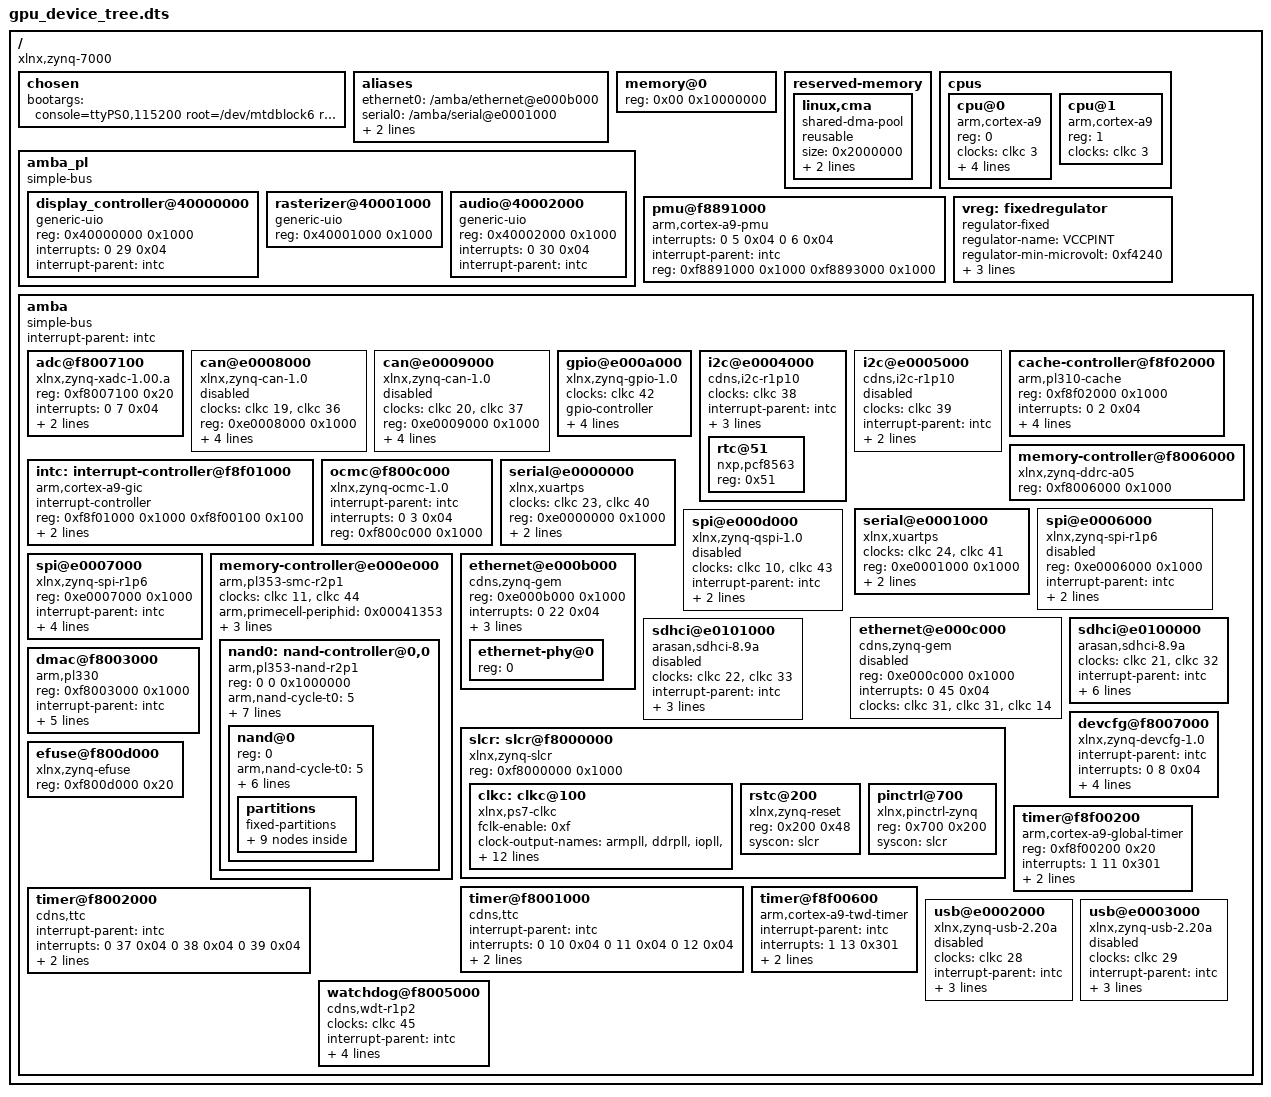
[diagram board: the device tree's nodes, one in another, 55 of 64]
/dts-v1/;

/* IRQ reference */
/* https://www.kernel.org/doc/Documentation/devicetree/bindings/interrupt-controller/arm%2Cgic.txt */
/* https://docs.xilinx.com/r/en-US/ug585-zynq-7000-SoC-TRM/Shared-Peripheral-Interrupts-SPI?tocId=LGXkQnG10uJNPCT_l2ZhDQ */
/* Subtract 32 from IRQ ID# in UG585 */

/ {
    #address-cells = <1>;
    #size-cells = <1>;
    compatible = "xlnx,zynq-7000";

    chosen {
        bootargs = "console=ttyPS0,115200 root=/dev/mtdblock6 rootfstype=jffs2 noinitrd rw rootwait uio_pdrv_genirq.of_id=generic-uio";
    };

    aliases {
        ethernet0 = "/amba/ethernet@e000b000";
        serial0 = "/amba/serial@e0001000";
        serial1 = "/amba/serial@e0000000";
        spi0 = "/amba/spi@e0007000";
    };

    memory@0 {
        device_type = "memory";
        reg = <0x00 0x10000000>;
    };

    reserved-memory {
        #address-cells = <1>;
        #size-cells = <1>;
        ranges;

        linux,cma {
            compatible = "shared-dma-pool";
            reusable;
            size = <0x2000000>;
            alignment = <0x1000>;
            linux,cma-default;
        };
    };

    amba_pl {
        #address-cells = <1>;
        #size-cells = <1>;
        compatible = "simple-bus";
        ranges;

        display_controller@40000000 {
            compatible = "generic-uio";
            reg = <0x40000000 0x1000>;
            interrupts = <0 29 0x04>;
            interrupt-parent = <&intc>;
        };

        rasterizer@40001000 {
            compatible = "generic-uio";
            reg = <0x40001000 0x1000>;
        };

        audio@40002000 {
            compatible = "generic-uio";
            reg = <0x40002000 0x1000>;
            interrupts = <0 30 0x04>;
            interrupt-parent = <&intc>;
        };
    };

    cpus {
        #address-cells = <1>;
        #size-cells = <0>;

        cpu@0 {
            compatible = "arm,cortex-a9";
            device_type = "cpu";
            reg = <0>;
            clocks = <&clkc 3>; /* cpu_6or4x */
            clock-latency = <0x3e8>;
            cpu0-supply = <&vreg>;
            operating-points = <0xa2c29 0xf4240 0x51614 0xf4240>;
        };

        cpu@1 {
            compatible = "arm,cortex-a9";
            device_type = "cpu";
            reg = <1>;
            clocks = <&clkc 3>; /* cpu_6or4x */
        };
    };

    pmu@f8891000 {
        compatible = "arm,cortex-a9-pmu";
        interrupts = <
            0 5 0x04
            0 6 0x04
        >;
        interrupt-parent = <&intc>;
        reg = <0xf8891000 0x1000 0xf8893000 0x1000>;
    };

    vreg: fixedregulator {
        compatible = "regulator-fixed";
        regulator-name = "VCCPINT";
        regulator-min-microvolt = <0xf4240>;
        regulator-max-microvolt = <0xf4240>;
        regulator-boot-on;
        regulator-always-on;
    };

    amba {
        compatible = "simple-bus";
        #address-cells = <1>;
        #size-cells = <1>;
        interrupt-parent = <&intc>;
        ranges;

        adc@f8007100 {
            compatible = "xlnx,zynq-xadc-1.00.a";
            reg = <0xf8007100 0x20>;
            interrupts = <0 7 0x04>;
            interrupt-parent = <&intc>;
            clocks = <&clkc 12>; /* pcap */
        };

        can@e0008000 {
            compatible = "xlnx,zynq-can-1.0";
            status = "disabled";
            clocks = <&clkc 19 &clkc 36>; /* can0, can0_aper */
            clock-names = "can_clk", "pclk";
            reg = <0xe0008000 0x1000>;
            interrupts = <0 28 0x04>;
            interrupt-parent = <&intc>;
            tx-fifo-depth = <0x40>;
            rx-fifo-depth = <0x40>;
        };

        can@e0009000 {
            compatible = "xlnx,zynq-can-1.0";
            status = "disabled";
            clocks = <&clkc 20 &clkc 37>; /* can1, can1_aper */
            clock-names = "can_clk", "pclk";
            reg = <0xe0009000 0x1000>;
            interrupts = <0 51 0x04>;
            interrupt-parent = <&intc>;
            tx-fifo-depth = <0x40>;
            rx-fifo-depth = <0x40>;
        };

        gpio@e000a000 {
            compatible = "xlnx,zynq-gpio-1.0";
            #gpio-cells = <2>;
            clocks = <&clkc 42>; /* gpio_aper */
            gpio-controller;
            interrupt-controller;
            #interrupt-cells = <2>;
            interrupt-parent = <&intc>;
            interrupts = <0 20 0x04>;
            reg = <0xe000a000 0x1000>;
        };

        i2c@e0004000 {
            compatible = "cdns,i2c-r1p10";
            status = "okay";
            clocks = <&clkc 38>; /* i2c0_aper */
            interrupt-parent = <&intc>;
            interrupts = <0 25 0x04>;
            reg = <0xe0004000 0x1000>;
            #address-cells = <1>;
            #size-cells = <0>;
            clock-frequency = <0x61a80>;

            rtc@51 {
                compatible = "nxp,pcf8563";
                reg = <0x51>;
            };
        };

        i2c@e0005000 {
            compatible = "cdns,i2c-r1p10";
            status = "disabled";
            clocks = <&clkc 39>; /* i2c1_aper */
            interrupt-parent = <&intc>;
            interrupts = <0 48 0x04>;
            reg = <0xe0005000 0x1000>;
            #address-cells = <1>;
            #size-cells = <0>;
        };

        intc: interrupt-controller@f8f01000 {
            compatible = "arm,cortex-a9-gic";
            #interrupt-cells = <3>;
            interrupt-controller;
            reg = <0xf8f01000 0x1000 0xf8f00100 0x100>;
            num_cpus = <0x02>;
            num_interrupts = <0x60>;
        };

        cache-controller@f8f02000 {
            compatible = "arm,pl310-cache";
            reg = <0xf8f02000 0x1000>;
            interrupts = <0 2 0x04>;
            arm,data-latency = <0x03 0x02 0x02>;
            arm,tag-latency = <0x02 0x02 0x02>;
            cache-unified;
            cache-level = <2>;
        };

        memory-controller@f8006000 {
            compatible = "xlnx,zynq-ddrc-a05";
            reg = <0xf8006000 0x1000>;
        };

        ocmc@f800c000 {
            compatible = "xlnx,zynq-ocmc-1.0";
            interrupt-parent = <&intc>;
            interrupts = <0 3 0x04>;
            reg = <0xf800c000 0x1000>;
        };

        serial@e0000000 {
            compatible = "xlnx,xuartps", "cdns,uart-r1p8";
            status = "okay";
            clocks = <&clkc 23 &clkc 40>; /* uart0, uart0_aper */
            clock-names = "uart_clk", "pclk";
            reg = <0xe0000000 0x1000>;
            interrupts = <0 27 0x04>;
            device_type = "serial";
            port-number = <1>;
        };

        serial@e0001000 {
            compatible = "xlnx,xuartps", "cdns,uart-r1p8";
            status = "okay";
            clocks = <&clkc 24 &clkc 41>; /* uart1, uart1_aper */
            clock-names = "uart_clk", "pclk";
            reg = <0xe0001000 0x1000>;
            interrupts = <0 50 0x04>;
            device_type = "serial";
            port-number = <0>;
        };

        spi@e0006000 {
            compatible = "xlnx,zynq-spi-r1p6";
            reg = <0xe0006000 0x1000>;
            status = "disabled";
            interrupt-parent = <&intc>;
            interrupts = <0 26 0x04>;
            clocks = <&clkc 25 &clkc 34>; /* spi0, spi0_aper */
            clock-names = "ref_clk", "pclk";
            #address-cells = <1>;
            #size-cells = <0>;
        };

        spi@e0007000 {
            compatible = "xlnx,zynq-spi-r1p6";
            reg = <0xe0007000 0x1000>;
            status = "okay";
            interrupt-parent = <&intc>;
            interrupts = <0 49 0x04>;
            clocks = <&clkc 26 &clkc 35>; /* spi1, spi1_aper */
            clock-names = "ref_clk", "pclk";
            #address-cells = <1>;
            #size-cells = <0>;
            is-decoded-cs = <0>;
            num-cs = <2>;
        };

        spi@e000d000 {
            clock-names = "ref_clk", "pclk";
            clocks = <&clkc 10 &clkc 43>; /* lqspi, lqspi_aper */
            compatible = "xlnx,zynq-qspi-1.0";
            status = "disabled";
            interrupt-parent = <&intc>;
            interrupts = <0 19 0x04>;
            reg = <0xe000d000 0x1000>;
            #address-cells = <1>;
            #size-cells = <0>;
        };

        memory-controller@e000e000 {
            status = "okay";
            #address-cells = <2>;
            #size-cells = <1>;
            clock-names = "memclk", "apb_pclk";
            clocks = <&clkc 11 &clkc 44>; /* smc, smc_aper */
            compatible = "arm,pl353-smc-r2p1", "arm,primecell";
            arm,primecell-periphid = <0x00041353>;
            interrupt-parent = <&intc>;
            interrupts = <0 18 0x04>;
            reg = <0xe000e000 0x1000>;
            ranges = <0x0 0x0 0xe1000000 0x1000000>; /* Nand CS region */

            nand0: nand-controller@0,0 {
                status = "okay";

                compatible = "arm,pl353-nand-r2p1";
                reg = <0 0 0x1000000>;
                #address-cells = <1>;
                #size-cells = <0>;
                arm,nand-cycle-t0 = <5>;
                arm,nand-cycle-t1 = <5>;
                arm,nand-cycle-t2 = <2>;
                arm,nand-cycle-t3 = <2>;
                arm,nand-cycle-t4 = <2>;
                arm,nand-cycle-t5 = <1>;
                arm,nand-cycle-t6 = <2>;

                cs-gpios = <0>;
                nand@0 {
                    status = "okay";
                    reg = <0>;
                    arm,nand-cycle-t0 = <5>;
                    arm,nand-cycle-t1 = <5>;
                    arm,nand-cycle-t2 = <2>;
                    arm,nand-cycle-t3 = <2>;
                    arm,nand-cycle-t4 = <2>;
                    arm,nand-cycle-t5 = <1>;
                    arm,nand-cycle-t6 = <2>;

                    partitions {
                        compatible = "fixed-partitions";
                        #address-cells = <1>;
                        #size-cells = <1>;

                        partition@0 {
                            label = "nand-fsbl-uboot";
                            reg = <0x00 0x300000>;
                        };

                        partition@300000 {
                            label = "nand-linux";
                            reg = <0x300000 0x500000>;
                        };

                        partition@800000 {
                            label = "nand-device-tree";
                            reg = <0x800000 0x20000>;
                        };

                        partition@820000 {
                            label = "nand-rootfs";
                            reg = <0x820000 0xa00000>;
                        };

                        partition@1220000 {
                            label = "nand-jffs2";
                            reg = <0x1220000 0x1000000>;
                        };

                        partition@2220000 {
                            label = "nand-bitstream";
                            reg = <0x2220000 0x800000>;
                        };

                        partition@2a20000 {
                            label = "nand-allrootfs";
                            reg = <0x2a20000 0x4000000>;
                        };

                        partition@6a20000 {
                            label = "nand-release";
                            reg = <0x6a20000 0x13e0000>;
                        };

                        partition@7e00000 {
                            label = "nand-reserve";
                            reg = <0x7e00000 0x200000>;
                        };
                    };
                };
            };
        };

        ethernet@e000b000 {
            compatible = "cdns,zynq-gem", "cdns,gem";
            reg = <0xe000b000 0x1000>;
            status = "okay";
            interrupts = <0 22 0x04>;
            clocks = <&clkc 30 &clkc 30 &clkc 13>; /* gem0_aper, gem0_aper, gem0 */
            clock-names = "pclk", "hclk", "tx_clk";
            #address-cells = <1>;
            #size-cells = <0>;
            local-mac-address = [00 0a 35 00 00 00];
            phy-mode = "mii";

            ethernet-phy@0 {
                reg = <0>;
            };
        };

        ethernet@e000c000 {
            compatible = "cdns,zynq-gem", "cdns,gem";
            reg = <0xe000c000 0x1000>;
            status = "disabled";
            interrupts = <0 45 0x04>;
            clocks = <&clkc 31 &clkc 31 &clkc 14>; /* gem1_aper, gem1_aper, gem1 */
            clock-names = "pclk", "hclk", "tx_clk";
            #address-cells = <1>;
            #size-cells = <0>;
        };

        sdhci@e0100000 {
            compatible = "arasan,sdhci-8.9a";
            status = "okay";
            clock-names = "clk_xin", "clk_ahb";
            clocks = <&clkc 21 &clkc 32>; /* sdio0, sdio0_aper */
            interrupt-parent = <&intc>;
            interrupts = <0 24 0x04>;
            reg = <0xe0100000 0x1000>;
            broken-adma2;
            xlnx,has-cd = <0>;
            xlnx,has-power = <0>;
            xlnx,has-wp = <0>;
        };

        sdhci@e0101000 {
            compatible = "arasan,sdhci-8.9a";
            status = "disabled";
            clock-names = "clk_xin", "clk_ahb";
            clocks = <&clkc 22 &clkc 33>; /* sdio1, sdio1_aper */
            interrupt-parent = <&intc>;
            interrupts = <0 47 0x04>;
            reg = <0xe0101000 0x1000>;
            broken-adma2;
        };

        slcr: slcr@f8000000 {
            #address-cells = <1>;
            #size-cells = <1>;
            compatible = "xlnx,zynq-slcr", "syscon", "simple-mfd";
            reg = <0xf8000000 0x1000>;
            ranges;

            clkc: clkc@100 {
                #clock-cells = <1>;
                compatible = "xlnx,ps7-clkc";
                fclk-enable = <0xf>;
                clock-output-names =
                    "armpll",     "ddrpll",     "iopll",      "cpu_6or4x",  "cpu_3or2x",
                    "cpu_2x",     "cpu_1x",     "ddr2x",      "ddr3x",      "dci",
                    "lqspi",      "smc",        "pcap",       "gem0",       "gem1",
                    "fclk0",      "fclk1",      "fclk2",      "fclk3",      "can0",
                    "can1",       "sdio0",      "sdio1",      "uart0",      "uart1",
                    "spi0",       "spi1",       "dma",        "usb0_aper",  "usb1_aper",
                    "gem0_aper",  "gem1_aper",  "sdio0_aper", "sdio1_aper", "spi0_aper",
                    "spi1_aper",  "can0_aper",  "can1_aper",  "i2c0_aper",  "i2c1_aper",
                    "uart0_aper", "uart1_aper", "gpio_aper",  "lqspi_aper", "smc_aper",
                    "swdt",       "dbg_trc",    "dbg_apb";
                reg = <0x100 0x100>;
                ps-clk-frequency = <33333333>;
            };

            rstc@200 {
                compatible = "xlnx,zynq-reset";
                reg = <0x200 0x48>;
                #reset-cells = <1>;
                syscon = <&slcr>;
            };

            pinctrl@700 {
                compatible = "xlnx,pinctrl-zynq";
                reg = <0x700 0x200>;
                syscon = <&slcr>;
            };
        };

        dmac@f8003000 {
            compatible = "arm,pl330", "arm,primecell";
            reg = <0xf8003000 0x1000>;
            interrupt-parent = <&intc>;
            interrupt-names = "abort", "dma0", "dma1", "dma2", "dma3", "dma4", "dma5", "dma6", "dma7";
            interrupts = <
                0 13 0x04
                0 14 0x04
                0 15 0x04
                0 16 0x04
                0 17 0x04
                0 40 0x04
                0 41 0x04
                0 42 0x04
                0 43 0x04
            >;
            #dma-cells = <1>;
            #dma-channels = <8>;
            #dma-requests = <4>;
            clocks = <&clkc 27>; /* dma */
            clock-names = "apb_pclk";
        };

        devcfg@f8007000 {
            compatible = "xlnx,zynq-devcfg-1.0";
            interrupt-parent = <&intc>;
            interrupts = <0 8 0x04>;
            reg = <0xf8007000 0x100>;
            clocks = <&clkc 12 &clkc 15 &clkc 16 &clkc 17 &clkc 18>; /* pcap, fclk0, fclk1, fclk2, fclk3 */
            clock-names = "ref_clk", "fclk0", "fclk1", "fclk2", "fclk3";
            syscon = <&slcr>;
        };

        efuse@f800d000 {
            compatible = "xlnx,zynq-efuse";
            reg = <0xf800d000 0x20>;
        };

        timer@f8f00200 {
            compatible = "arm,cortex-a9-global-timer";
            reg = <0xf8f00200 0x20>;
            interrupts = <1 11 0x301>;
            interrupt-parent = <&intc>;
            clocks = <&clkc 4>; /* cpu_3or2x */
        };

        timer@f8001000 {
            interrupt-parent = <&intc>;
            interrupts = <
                0 10 0x04
                0 11 0x04
                0 12 0x04
            >;
            compatible = "cdns,ttc";
            clocks = <&clkc 6>; /* cpu_1x */
            reg = <0xf8001000 0x1000>;
        };

        timer@f8002000 {
            interrupt-parent = <&intc>;
            interrupts = <
                0 37 0x04
                0 38 0x04
                0 39 0x04
            >;
            compatible = "cdns,ttc";
            clocks = <&clkc 6>; /* cpu_1x */
            reg = <0xf8002000 0x1000>;
        };

        timer@f8f00600 {
            interrupt-parent = <&intc>;
            interrupts = <1 13 0x301>;
            compatible = "arm,cortex-a9-twd-timer";
            reg = <0xf8f00600 0x20>;
            clocks = <&clkc 4>; /* cpu_3or2x */
        };

        usb@e0002000 {
            compatible = "xlnx,zynq-usb-2.20a", "chipidea,usb2";
            status = "disabled";
            clocks = <&clkc 28>; /* usb0_aper */
            interrupt-parent = <&intc>;
            interrupts = <0 21 0x04>;
            reg = <0xe0002000 0x1000>;
            phy_type = "ulpi";
        };

        usb@e0003000 {
            compatible = "xlnx,zynq-usb-2.20a", "chipidea,usb2";
            status = "disabled";
            clocks = <&clkc 29>; /* usb1_aper */
            interrupt-parent = <&intc>;
            interrupts = <0 44 0x04>;
            reg = <0xe0003000 0x1000>;
            phy_type = "ulpi";
        };

        watchdog@f8005000 {
            clocks = <&clkc 45>; /* swdt */
            compatible = "cdns,wdt-r1p2";
            interrupt-parent = <&intc>;
            interrupts = <0 9 0x01>;
            reg = <0xf8005000 0x1000>;
            timeout-sec = <10>;
            status = "okay";
            reset-on-timeout;
        };
    };
};
